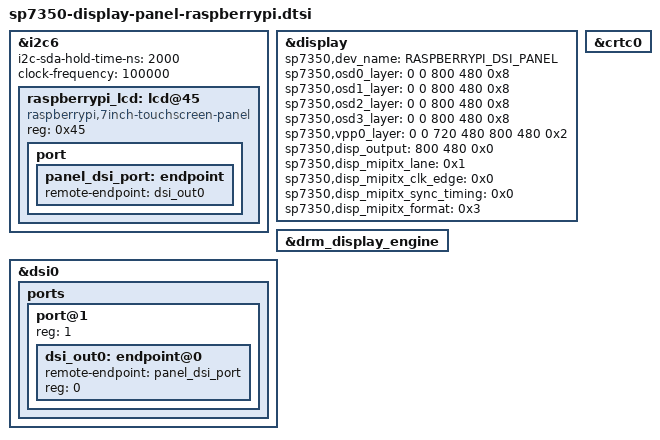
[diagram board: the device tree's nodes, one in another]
// SPDX-License-Identifier: (GPL-2.0 OR MIT)
/* Copyright (c) 2018-2024 Sunplus */

&i2c6 {
	i2c-sda-hold-time-ns = <2000>;
	clock-frequency = <100000>;

	#address-cells = <1>;
	#size-cells = <0>;

	raspberrypi_lcd: lcd@45 {
		compatible = "raspberrypi,7inch-touchscreen-panel";
		reg = <0x45>;
		port {
			panel_dsi_port: endpoint {
			remote-endpoint = <&dsi_out0>;
			};
		};
	};

};

&display {
	sp7350,dev_name = "RASPBERRYPI_DSI_PANEL";
	sp7350,osd0_layer = <0 0 800 480 0x8>; /* 0x8 = RGB565 */
	sp7350,osd1_layer = <0 0 800 480 0x8>; /* 0x8 = RGB565 */
	sp7350,osd2_layer = <0 0 800 480 0x8>; /* 0x8 = RGB565 */
	sp7350,osd3_layer = <0 0 800 480 0x8>; /* 0x8 = RGB565 */
	sp7350,vpp0_layer = <0 0 720 480 800 480 0x2>; /* 0x2 = YUY2 */
	sp7350,disp_output = <800 480 0x0>; /* 0x0:MIPITX DSI */
	sp7350,disp_mipitx_lane = <0x1>; /* 0x0:MIPITX lane */
	sp7350,disp_mipitx_clk_edge = <0x0>; /* 0x0:Raising Edge */
	sp7350,disp_mipitx_sync_timing = <0x0>; /* 0x0:Sync Pulse */
	sp7350,disp_mipitx_format = <0x3>; /* 0x3:MIPITX DSI RGB888 */
};


//TODO: should move to the main board dts configure files.
&drm_display_engine {
	status = "okay";
};
&crtc0 {
	status = "okay";
};
&dsi0 {
	status = "okay";

	ports {
		/* 1 for output port */
		port@1 {
			#address-cells = <1>;
			#size-cells = <0>;
			reg = <1>;
			dsi_out0: endpoint@0 {
				remote-endpoint = <&panel_dsi_port>;
				reg = <0>;
			};
		};

	};
};

